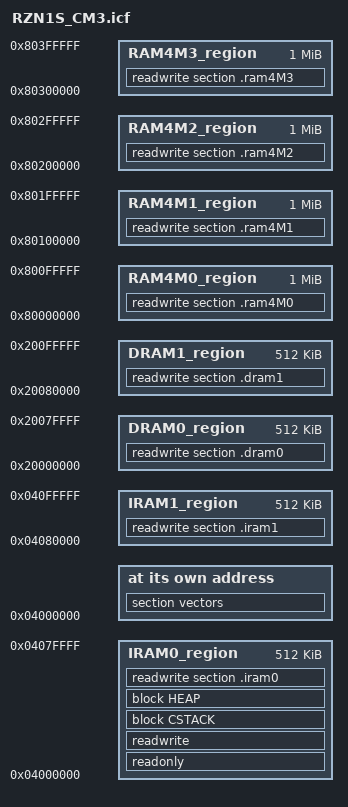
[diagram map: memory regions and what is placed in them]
/*###ICF### Section handled by ICF editor, don't touch! ****/
/*-Editor annotation file-*/
/* IcfEditorFile="$TOOLKIT_DIR$\config\ide\IcfEditor\a_v1_1.xml" */
/*-Specials-*/
define symbol __ICFEDIT_intvec_start__ = 0x04000000;
/*-Memory Regions-*/
define symbol __ICFEDIT_region_ROM_start__   = 0x00000000;
define symbol __ICFEDIT_region_ROM_end__     = 0x00000000;
define symbol __ICFEDIT_region_RAM_start__   = 0x00000000;
define symbol __ICFEDIT_region_RAM_end__     = 0x000FFFFF;
/*-Sizes-*/
define symbol __ICFEDIT_size_cstack__ = 0x8000;
define symbol __ICFEDIT_size_heap__   = 0x8000;
/**** End of ICF editor section. ###ICF###*/

define symbol _region_IRAM0_start__    = 0x04000000;
define symbol _region_IRAM0_end__      = 0x0407FFFF;
define symbol _region_IRAM1_start__    = 0x04080000;
define symbol _region_IRAM1_end__      = 0x040FFFFF;
define symbol _region_DRAM0_start__    = 0x20000000;
define symbol _region_DRAM0_end__      = 0x2007FFFF;
define symbol _region_DRAM1_start__    = 0x20080000;
define symbol _region_DRAM1_end__      = 0x200FFFFF;

define symbol _region_RAM4M0_start__   = 0x80000000;
define symbol _region_RAM4M0_end__     = 0x800FFFFF;
define symbol _region_RAM4M1_start__   = 0x80100000;
define symbol _region_RAM4M1_end__     = 0x801FFFFF;
define symbol _region_RAM4M2_start__   = 0x80200000;
define symbol _region_RAM4M2_end__     = 0x802FFFFF;
define symbol _region_RAM4M3_start__   = 0x80300000;
define symbol _region_RAM4M3_end__     = 0x803FFFFF;

define memory mem with size = 4G;

define region IRAM0_region = mem:[from _region_IRAM0_start__ to _region_IRAM0_end__];
define region IRAM1_region = mem:[from _region_IRAM1_start__ to _region_IRAM1_end__];
define region DRAM0_region = mem:[from _region_DRAM0_start__ to _region_DRAM0_end__];
define region DRAM1_region = mem:[from _region_DRAM1_start__ to _region_DRAM1_end__];

define region RAM4M0_region = mem:[from _region_RAM4M0_start__ to _region_RAM4M0_end__];
define region RAM4M1_region = mem:[from _region_RAM4M1_start__ to _region_RAM4M1_end__];
define region RAM4M2_region = mem:[from _region_RAM4M2_start__ to _region_RAM4M2_end__];
define region RAM4M3_region = mem:[from _region_RAM4M3_start__ to _region_RAM4M3_end__];

define block CSTACK    with alignment = 8, size = __ICFEDIT_size_cstack__   { };
define block HEAP      with alignment = 8, size = __ICFEDIT_size_heap__     { };

do not initialize  { section .noinit };
initialize by copy { readwrite } except { rw data section vectors };

place at address mem:__ICFEDIT_intvec_start__ { section vectors };
place in IRAM0_region { readonly };
place in IRAM0_region { readwrite};
place in IRAM0_region { block CSTACK, block HEAP };

place in IRAM0_region   {readwrite section .iram0};
place in IRAM1_region   {readwrite section .iram1};
place in DRAM0_region   {readwrite section .dram0};
place in DRAM1_region   {readwrite section .dram1};

place in RAM4M0_region   {readwrite section .ram4M0};
place in RAM4M1_region   {readwrite section .ram4M1};
place in RAM4M2_region   {readwrite section .ram4M2};
place in RAM4M3_region   {readwrite section .ram4M3};
